# a33g52x register map
Vendor: ABOV Semiconductor Co., Ltd.; File version: 0.1
CPU: CM3 r1p0, little endian, no MPU, no FPU, 3 interrupt priority bits
Registers are 32-bit, read-write, reset 0x0 unless marked. A register's access mark holds for its fields unless they carry their own. Offsets are from the block's base; [hi:lo] are bit positions; {n}, {i} and the like mark numbered series.

## ADC — 12-BIT A/D CONVERTER
Base 0x40000E00
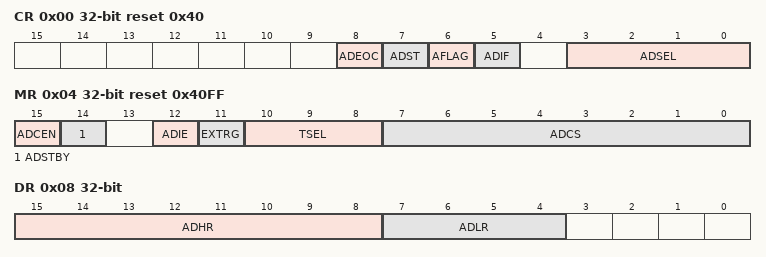
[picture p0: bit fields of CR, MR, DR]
0x00 CR reset 0x40 — ADC Control Register
  [8] ADEOC ro — A/D Conversion Status (Read/Only)
  [7] ADST — A/D Conversion Start
  [6] AFLAG — A/D Conversion Status Flag (Read-Only)
  [5] ADIF — A/D Converter interrupt Flag
  [3:0] ADSEL — Select ADC input channel(0~15)
0x04 MR reset 0x40FF — ADC Mode Register
  [15] ADCEN — Select ADC Enable
  [14] ADSTBY — Select ADC Stand-by mode
  [12] ADIE — Select End-of-Conversion interrupt
  [11] EXTRG — Select external trigger condition for start conversion
  [10:8] TSEL — SOC trigger source
  [7:0] ADCS — Select A/D conversion clock
0x08 DR ro — A/D Data Register
  [15:8] ADHR — Upper byte of A/D conversion data
  [7:4] ADLR — Lower byte of A/D conversion data

## FMC — INTERNAL FLASH MEMORY
Base 0x40000100
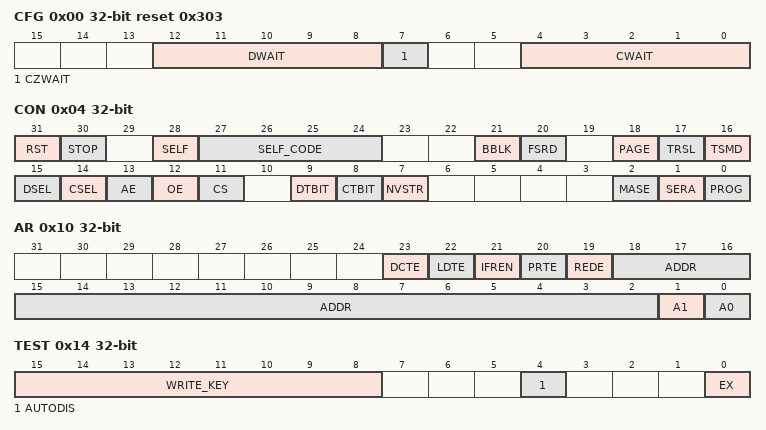
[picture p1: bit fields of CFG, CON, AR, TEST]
0x00 CFG reset 0x303 — Flash Memory Configuration Register
  [12:8] DWAIT — Wait value of data flash memory
  [7] CZWAIT — Zero wait value of code flash memory
  [4:0] CWAIT — Wait value of code flash memory
0x04 CON — Flash Memory Control Register
  [31] RST — Flash Reset Signal Control
  [30] STOP — Flash Status Control
  [28] SELF — Flash Self Program Control
  [27:24] SELF_CODE — Flash self program mode, can be written in conjunction with the PMCON[27:24] = 0110
  [21] BBLK — Boot Block Protection
  [20] FSRD — Fuse area activation(for flash internal test)
  [18] PAGE — Erase flash on a page(512 bytes) unit. Not supported in self-program mode
  [17] TRSL — Allow access to registers for flash testing(For flash internal test)
  [16] TSMD — Enter Test Mode(for flash internal test)
  [15] DSEL — Data Flash Select
  [14] CSEL — Code Flash Select
  [13] AE — Address Latch Enable
  [12] OE — Output Enable(Code flash program mode)
  [11] CS — Chip Select(Select Flash Rom)
  [9] DTBIT ro — Data Flash WRITE/ERASE Status Flag
  [8] CTBIT ro — Code Flash WRITE/ERASE Status Flag
  [7] NVSTR — Flash Memory WRITE/ERASE Start
  [2] MASE — Select Code or Data Flash Macro Erase
  [1] SERA — Erase flash in sectors(1KB) unit
  [0] PROG — Select Code or Data Flash for Write
0x08 ODR — Flash Memory Output Data Register
  [31:0] ODR — Output Data to the Flash Memories
0x0C IDR ro — Flash Memory Input Data Register
  [31:0] FMIDR — Input Data from the Flash Memories
0x10 AR — Flash Memory Address Register
  [23] DCTE — Always 0 (prohibited to write 1)
  [22] LDTE — Always 0 (prohibited to write 1)
  [21] IFREN — Always 0 (prohibited to write 1)
  [20] PRTE — Always 0 (prohibited to write 1)
  [19] REDE — Always 0 (prohibited to write 1)
  [18:2] ADDR — Flash Memory Address Value
  [1] A1 — Address A1 for Data Flash Memory
  [0] A0 — Address A0 for Data Flash Memory
0x14 TEST — Flash Memory Extended Mode Control Register
  [15:8] WRITE_KEY — To write values to the AUTODIS and EX fields, you must write the WRITE KEY. (WRITE KEY: 0x4A)
  [4] AUTODIS — NVSTR auto-clear
  [0] EX — Extended mode enable/disable
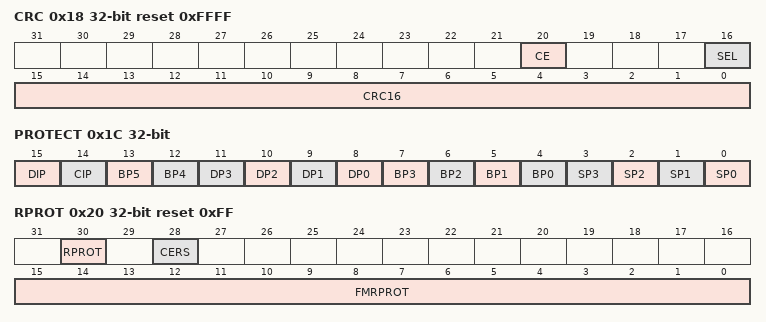
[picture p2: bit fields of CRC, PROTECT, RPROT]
0x18 CRC reset 0xFFFF — Flash Memory CRC Register
  [20] CE — CRC16 Enable/Disable
  [16] SEL — Selecting data to be input to CRC16
  [15:0] CRC16 — CRC16 Calculated value
0x1C PROTECT — Flash Memory Protection Register
  [15] DIP — Always 0
  [14] CIP — Always 0
  [13] BP5 — Protection bit from 0x0005_0000 to 0x0005_FFFF
  [12] BP4 — Protection bit from 0x0004_0000 to 0x0004_FFFF
  [n+8] DP{n} (n=0..3) — Protection bit of the Data Flash 8KB #{n}
  [7] BP3 — Protection bit from 0x0003_0000 to 0x0003_FFFF
  [6] BP2 — Protection bit from 0x0002_0000 to 0x0002_FFFF
  [5] BP1 — Protection bit from 0x0001_0000 to 0x0001_FFFF
  [4] BP0 — Protection bit from 0x0000_4000 to 0x0000_FFFF
  [n] SP{n} (n=0..3) — Protection bit from 0x0000_{1000n:04} to 0x0000_{n}FFF
0x20 RPROT reset 0xFF (reset mask 0x500000FF) — Flash Memory Read Protection Register
  [30] RPROT — Read Protection Status enable/disable
  [28] CERS — Chip Erase Status.This bit is set to 1 when the Chip Erase command is executed during the erase command
  [15:0] FMRPROT — Read Protection Setting

## MEMCR — Memory Control Register
Base 0x400000E0
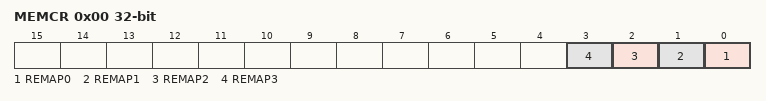
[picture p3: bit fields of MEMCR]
0x00 MEMCR — Memory Control Register
  [n] REMAP{n} (n=0..3) — Remap {0x0+0x1000*n} ~ {0xFFF+0x1000*n} Area (Area {n})

## PMULEGACY — PMULEGACY HART-m310 Extended Mode Register
Base 0x400000F8
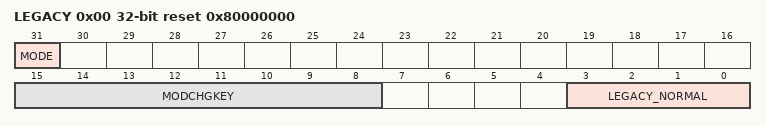
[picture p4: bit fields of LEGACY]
0x00 LEGACY reset 0x80000000 — LEGACY HART-m310 Extended Mode Register
  [31] MODE ro — Mode Status Bit
  [15:8] MODCHGKEY wo — Mode Change Key
  [3:0] LEGACY_NORMAL — Legacy_Normal mode change

## CHIPCONFIG
Base 0x4000F000
0x00 VENDORID ro reset 0x41424F56
0x04 CHIPID ro reset 0x4D33A000
